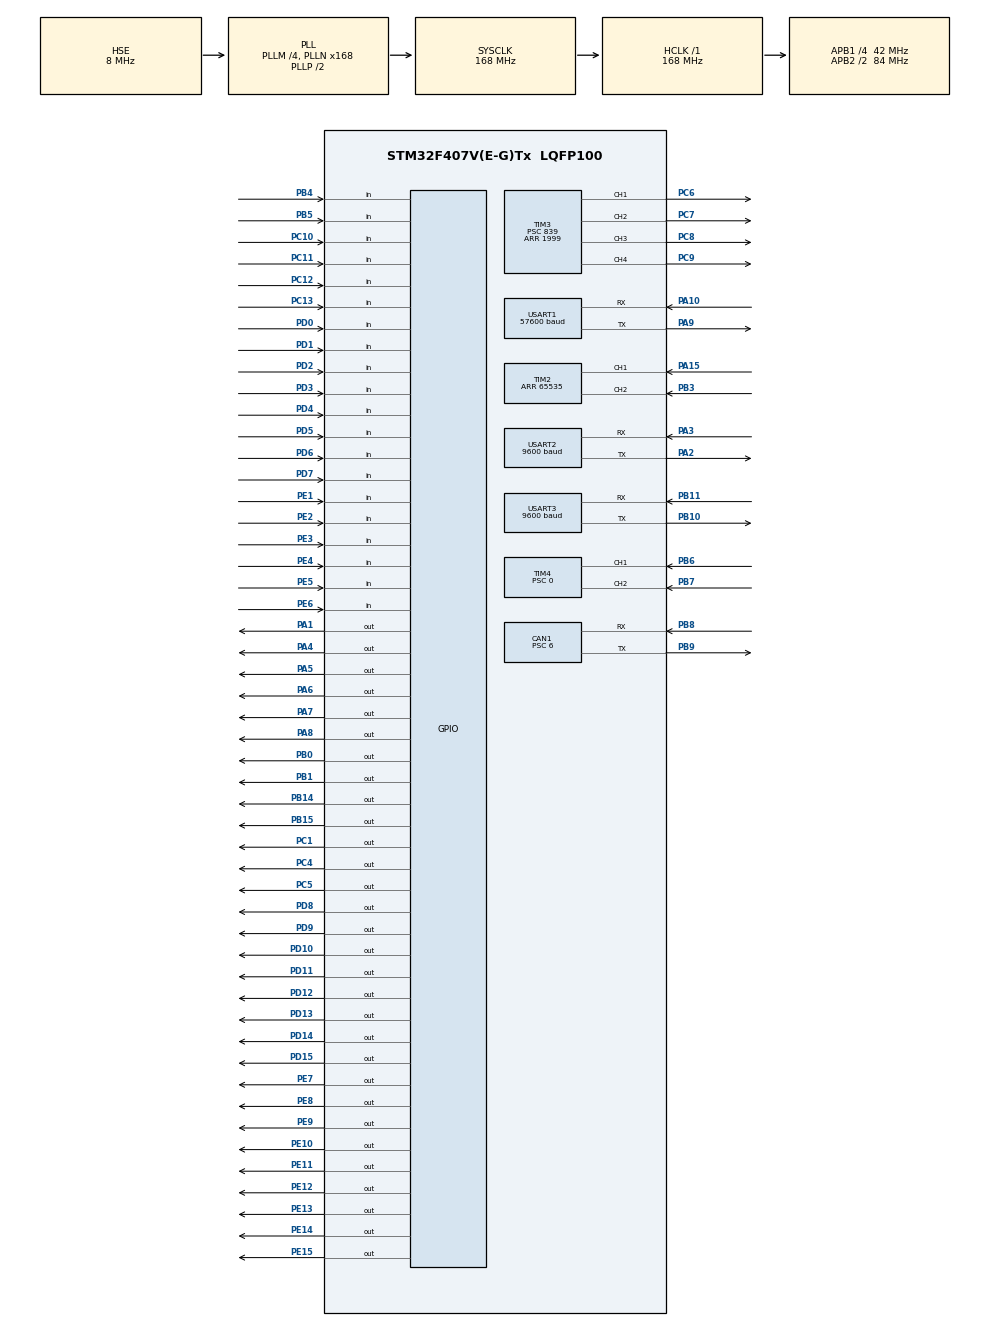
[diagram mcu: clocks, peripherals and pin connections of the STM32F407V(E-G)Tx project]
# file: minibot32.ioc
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CAN1.ABOM=ENABLE
CAN1.BS1=CAN_BS1_11TQ
CAN1.BS2=CAN_BS2_2TQ
CAN1.CalculateBaudRate=500000
CAN1.CalculateTimeBit=2000
CAN1.CalculateTimeQuantum=142.85714285714286
CAN1.Prescaler=6
CAN1.TXFP=ENABLE
Dma.Request0=USART1_RX
Dma.Request1=USART2_RX
Dma.Request2=USART3_RX
Dma.USART1_RX.0.Direction=DMA_PERIPH_TO_MEMORY
Dma.USART1_RX.0.FIFOMode=DMA_FIFOMODE_DISABLE
Dma.USART1_RX.0.Instance=DMA2_Stream2
Dma.USART1_RX.0.MemDataAlignment=DMA_MDATAALIGN_BYTE
Dma.USART1_RX.0.MemInc=DMA_MINC_ENABLE
Dma.USART1_RX.0.Mode=DMA_NORMAL
Dma.USART1_RX.0.PeriphDataAlignment=DMA_PDATAALIGN_BYTE
Dma.USART1_RX.0.PeriphInc=DMA_PINC_DISABLE
Dma.USART1_RX.0.Priority=DMA_PRIORITY_LOW
Dma.USART2_RX.1.Direction=DMA_PERIPH_TO_MEMORY
Dma.USART2_RX.1.FIFOMode=DMA_FIFOMODE_DISABLE
Dma.USART2_RX.1.Instance=DMA1_Stream5
Dma.USART2_RX.1.MemDataAlignment=DMA_MDATAALIGN_BYTE
Dma.USART2_RX.1.MemInc=DMA_MINC_ENABLE
Dma.USART2_RX.1.Mode=DMA_NORMAL
Dma.USART2_RX.1.PeriphDataAlignment=DMA_PDATAALIGN_BYTE
Dma.USART2_RX.1.PeriphInc=DMA_PINC_DISABLE
Dma.USART2_RX.1.Priority=DMA_PRIORITY_LOW
Dma.USART3_RX.2.Direction=DMA_PERIPH_TO_MEMORY
Dma.USART3_RX.2.FIFOMode=DMA_FIFOMODE_DISABLE
Dma.USART3_RX.2.Instance=DMA1_Stream1
Dma.USART3_RX.2.MemDataAlignment=DMA_MDATAALIGN_BYTE
Dma.USART3_RX.2.MemInc=DMA_MINC_ENABLE
Dma.USART3_RX.2.Mode=DMA_NORMAL
Dma.USART3_RX.2.PeriphDataAlignment=DMA_PDATAALIGN_BYTE
Dma.USART3_RX.2.PeriphInc=DMA_PINC_DISABLE
Dma.USART3_RX.2.Priority=DMA_PRIORITY_LOW
FREERTOS.Tasks01=defaultTask,24,128,StartDefaultTask,Default,NULL,Static,defaultTaskBuffer,defaultTaskControlBlock;OutputsTask,24,128,StartOutputsTask,As external,NULL,Static,OutputsTaskBuffer,OutputsTaskControlBlock;InputsTask,24,128,StartInputsTask,As external,NULL,Static,InputsTaskBuffer,InputsTaskControlBlock;ServoTask,24,128,StartServoTask,As external,NULL,Static,ServoTaskBuffer,ServoTaskControlBlock;UartWiFiTask,24,256,StartUartWiFiTask,As external,NULL,Static,UartWiFiTaskBuffer,UartWiFiTaskControlBlock;CanDriversTask,24,128,StartCanDriversTask,As external,NULL,Static,CanDriversTaskBuffer,CanDriversTaskControlBlock;CanTask,24,256,StartCanTask,As external,NULL,Static,CanTaskBuffer,CanTaskControlBlock;MissionsTask,8,256,StartMissionsTask,As external,NULL,Static,MissionsTaskBuffer,MissionsTaskControlBlock
IWDG.Prescaler=IWDG_PRESCALER_32
Mcu.Family=STM32F4
Mcu.Name=STM32F407V(E-G)Tx
Mcu.Package=LQFP100
NVIC.CAN1_RX0_IRQn=true\:5\:0\:false\:false\:true\:true\:true\:true\:true
NVIC.CAN1_SCE_IRQn=true\:5\:0\:false\:false\:true\:true\:true\:true\:true
NVIC.DMA1_Stream1_IRQn=true\:5\:0\:false\:false\:true\:true\:false\:true\:true
NVIC.DMA1_Stream5_IRQn=true\:5\:0\:false\:false\:true\:true\:false\:true\:true
NVIC.DMA2_Stream2_IRQn=true\:5\:0\:false\:false\:true\:true\:false\:true\:true
NVIC.PriorityGroup=NVIC_PRIORITYGROUP_4
NVIC.TIM6_DAC_IRQn=true\:15\:0\:false\:false\:true\:false\:false\:true\:true
NVIC.TimeBase=TIM6_DAC_IRQn
NVIC.TimeBaseIP=TIM6
NVIC.USART1_IRQn=true\:5\:0\:false\:false\:true\:true\:true\:true\:true
NVIC.USART2_IRQn=true\:5\:0\:false\:false\:true\:true\:true\:true\:true
NVIC.USART3_IRQn=true\:5\:0\:false\:false\:true\:true\:true\:true\:true
PA1.PinState=GPIO_PIN_SET
PA1.Signal=GPIO_Output
PA10.Mode=Asynchronous
PA10.Signal=USART1_RX
PA13.Mode=Serial_Wire
PA13.Signal=SYS_JTMS-SWDIO
PA14.Mode=Serial_Wire
PA14.Signal=SYS_JTCK-SWCLK
PA15.Signal=S_TIM2_CH1_ETR
PA2.Mode=Asynchronous
PA2.Signal=USART2_TX
PA3.Mode=Asynchronous
PA3.Signal=USART2_RX
PA4.PinState=GPIO_PIN_SET
PA4.Signal=GPIO_Output
PA5.PinState=GPIO_PIN_SET
PA5.Signal=GPIO_Output
PA6.PinState=GPIO_PIN_SET
PA6.Signal=GPIO_Output
PA7.PinState=GPIO_PIN_SET
PA7.Signal=GPIO_Output
PA8.PinState=GPIO_PIN_SET
PA8.Signal=GPIO_Output
PA9.Mode=Asynchronous
PA9.Signal=USART1_TX
PB0.PinState=GPIO_PIN_SET
PB0.Signal=GPIO_Output
PB1.PinState=GPIO_PIN_SET
PB1.Signal=GPIO_Output
PB10.Mode=Asynchronous
PB10.Signal=USART3_TX
PB11.Mode=Asynchronous
PB11.Signal=USART3_RX
PB14.Signal=GPIO_Output
PB15.Signal=GPIO_Output
PB3.Signal=S_TIM2_CH2
PB4.Signal=GPIO_Input
PB5.Signal=GPIO_Input
PB6.Signal=S_TIM4_CH1
PB7.Signal=S_TIM4_CH2
PB8.Mode=CAN_Activate
PB8.Signal=CAN1_RX
PB9.Mode=CAN_Activate
PB9.Signal=CAN1_TX
PC1.PinState=GPIO_PIN_SET
PC1.Signal=GPIO_Output
PC10.Signal=GPIO_Input
PC11.Signal=GPIO_Input
PC12.Signal=GPIO_Input
PC13-ANTI_TAMP.Signal=GPIO_Input
PC14-OSC32_IN.Mode=LSE-External-Oscillator
PC14-OSC32_IN.Signal=RCC_OSC32_IN
PC15-OSC32_OUT.Mode=LSE-External-Oscillator
PC15-OSC32_OUT.Signal=RCC_OSC32_OUT
PC4.PinState=GPIO_PIN_SET
PC4.Signal=GPIO_Output
PC5.PinState=GPIO_PIN_SET
PC5.Signal=GPIO_Output
PC6.Signal=S_TIM3_CH1
PC7.Signal=S_TIM3_CH2
PC8.Signal=S_TIM3_CH3
PC9.Signal=S_TIM3_CH4
PD0.Signal=GPIO_Input
PD1.Signal=GPIO_Input
PD10.PinState=GPIO_PIN_SET
PD10.Signal=GPIO_Output
PD11.PinState=GPIO_PIN_SET
PD11.Signal=GPIO_Output
PD12.PinState=GPIO_PIN_SET
PD12.Signal=GPIO_Output
PD13.PinState=GPIO_PIN_SET
PD13.Signal=GPIO_Output
PD14.Signal=GPIO_Output
PD15.PinState=GPIO_PIN_SET
PD15.Signal=GPIO_Output
PD2.Signal=GPIO_Input
PD3.Signal=GPIO_Input
PD4.Signal=GPIO_Input
PD5.Signal=GPIO_Input
PD6.Signal=GPIO_Input
PD7.Signal=GPIO_Input
PD8.PinState=GPIO_PIN_SET
PD8.Signal=GPIO_Output
PD9.PinState=GPIO_PIN_SET
PD9.Signal=GPIO_Output
PE1.Signal=GPIO_Input
PE10.PinState=GPIO_PIN_SET
PE10.Signal=GPIO_Output
PE11.PinState=GPIO_PIN_SET
PE11.Signal=GPIO_Output
PE12.PinState=GPIO_PIN_SET
PE12.Signal=GPIO_Output
PE13.PinState=GPIO_PIN_SET
PE13.Signal=GPIO_Output
PE14.PinState=GPIO_PIN_SET
PE14.Signal=GPIO_Output
PE15.PinState=GPIO_PIN_SET
PE15.Signal=GPIO_Output
PE2.Signal=GPIO_Input
PE3.Signal=GPIO_Input
PE4.Signal=GPIO_Input
PE5.Signal=GPIO_Input
PE6.Signal=GPIO_Input
PE7.PinState=GPIO_PIN_SET
PE7.Signal=GPIO_Output
PE8.PinState=GPIO_PIN_SET
PE8.Signal=GPIO_Output
PE9.PinState=GPIO_PIN_SET
PE9.Signal=GPIO_Output
PH0-OSC_IN.Mode=HSE-External-Oscillator
PH0-OSC_IN.Signal=RCC_OSC_IN
PH1-OSC_OUT.Mode=HSE-External-Oscillator
PH1-OSC_OUT.Signal=RCC_OSC_OUT
ProjectManager.HeapSize=0x200
ProjectManager.StackSize=0x400
ProjectManager.TargetToolchain=STM32CubeIDE
RCC.48MHZClocksFreq_Value=84000000
RCC.AHBFreq_Value=168000000
RCC.APB1CLKDivider=RCC_HCLK_DIV4
RCC.APB1Freq_Value=42000000
RCC.APB1TimFreq_Value=84000000
RCC.APB2CLKDivider=RCC_HCLK_DIV2
RCC.APB2Freq_Value=84000000
RCC.APB2TimFreq_Value=168000000
RCC.CortexFreq_Value=168000000
RCC.HCLKFreq_Value=168000000
RCC.HSE_VALUE=8000000
RCC.HSI_VALUE=16000000
RCC.PLLM=4
RCC.PLLN=168
RCC.PLLSourceVirtual=RCC_PLLSOURCE_HSE
RCC.SYSCLKFreq_VALUE=168000000
RCC.SYSCLKSource=RCC_SYSCLKSOURCE_PLLCLK
RCC.VCOOutputFreq_Value=336000000
SH.S_TIM2_CH1_ETR.0=TIM2_CH1,Encoder_Interface
SH.S_TIM2_CH2.0=TIM2_CH2,Encoder_Interface
SH.S_TIM3_CH1.0=TIM3_CH1,PWM Generation1 CH1
SH.S_TIM3_CH2.0=TIM3_CH2,PWM Generation2 CH2
SH.S_TIM3_CH3.0=TIM3_CH3,PWM Generation3 CH3
SH.S_TIM3_CH4.0=TIM3_CH4,PWM Generation4 CH4
SH.S_TIM4_CH1.0=TIM4_CH1,Encoder_Interface
SH.S_TIM4_CH2.0=TIM4_CH2,Encoder_Interface
TIM2.Period=65535
TIM3.AutoReloadPreload=TIM_AUTORELOAD_PRELOAD_ENABLE
TIM3.Channel-PWM\ Generation1\ CH1=TIM_CHANNEL_1
TIM3.Channel-PWM\ Generation2\ CH2=TIM_CHANNEL_2
TIM3.Channel-PWM\ Generation3\ CH3=TIM_CHANNEL_3
TIM3.Channel-PWM\ Generation4\ CH4=TIM_CHANNEL_4
TIM3.OCPolarity_1=TIM_OCPOLARITY_HIGH
TIM3.Period=1999
TIM3.Prescaler=839
TIM4.Period=65535
TIM4.Prescaler=0
USART1.BaudRate=57600
USART1.VirtualMode=VM_ASYNC
USART2.BaudRate=9600
USART2.VirtualMode=VM_ASYNC
USART3.BaudRate=9600
USART3.VirtualMode=VM_ASYNC
VP_FREERTOS_VS_CMSIS_V2.Mode=CMSIS_V2
VP_IWDG_VS_IWDG.Mode=IWDG_Activate
VP_SYS_VS_tim6.Mode=TIM6
VP_TIM3_VS_ClockSourceINT.Mode=Internal
board=custom

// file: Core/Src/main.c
/* USER CODE BEGIN Header */
/**
  ******************************************************************************
  * @file           : main.c
  * @brief          : Main program body
  ******************************************************************************
  * @attention
  *
  * Copyright (c) 2024 STMicroelectronics.
  * All rights reserved.
  *
  * This software is licensed under terms that can be found in the LICENSE file
  * in the root directory of this software component.
  * If no LICENSE file comes with this software, it is provided AS-IS.
  *
  ******************************************************************************
  */
/* USER CODE END Header */
#include "main.h"
#include "cmsis_os.h"
#include "can.h"
#include "dma.h"
#include "iwdg.h"
#include "tim.h"
#include "usart.h"
#include "gpio.h"

/* USER CODE BEGIN Includes */

#include "minibot_config.h"

/* USER CODE END Includes */

/* USER CODE BEGIN PV */

extern DMA_HandleTypeDef RC_UART_DMA;
extern DMA_HandleTypeDef BMS_UART_DMA;
extern DMA_HandleTypeDef WIFI_UART_DMA;

extern uint8_t rc_uart_buff[100];
extern uint8_t bms_uart_buff[100];
extern uint8_t wifi_uart_buff[100];

/* USER CODE END PV */

void SystemClock_Config(void);
void MX_FREERTOS_Init(void);

int main(void)
{

  /* MCU Configuration--------------------------------------------------------*/

  /* Reset of all peripherals, Initializes the Flash interface and the Systick. */
  HAL_Init();

  /* Configure the system clock */
  SystemClock_Config();

  /* Initialize all configured peripherals */
  MX_GPIO_Init();
  MX_DMA_Init();
  MX_USART1_UART_Init();
  MX_USART2_UART_Init();
  MX_USART3_UART_Init();
  MX_TIM2_Init();
  MX_TIM3_Init();
  MX_TIM4_Init();
  MX_IWDG_Init();
  MX_CAN1_Init();
  /* USER CODE BEGIN 2 */
  HAL_Delay(2500);
  HAL_IWDG_Refresh(&hiwdg);
  HAL_UARTEx_ReceiveToIdle_DMA(&WIFI_UART, wifi_uart_buff, sizeof(wifi_uart_buff));
  HAL_UARTEx_ReceiveToIdle_DMA(&BMS_UART, bms_uart_buff, sizeof(bms_uart_buff));
  HAL_UARTEx_ReceiveToIdle_DMA(&RC_UART, rc_uart_buff, sizeof(rc_uart_buff));

  __HAL_DMA_DISABLE_IT(&WIFI_UART_DMA, DMA_IT_HT);
  __HAL_DMA_DISABLE_IT(&BMS_UART_DMA, DMA_IT_HT);
  __HAL_DMA_DISABLE_IT(&RC_UART_DMA, DMA_IT_HT);

  HAL_TIM_Encoder_Start(&htim2, TIM_CHANNEL_1);
  HAL_TIM_Encoder_Start(&htim4, TIM_CHANNEL_1);
  /* USER CODE END 2 */

  /* Init scheduler */
  osKernelInitialize();  /* Call init function for freertos objects (in freertos.c) */
  MX_FREERTOS_Init();

  /* Start scheduler */
  osKernelStart();

  /* We should never get here as control is now taken by the scheduler */
  /* Infinite loop */
  while (1)
  {

  }
}

void SystemClock_Config(void)
{
  RCC_OscInitTypeDef RCC_OscInitStruct = {0};
  RCC_ClkInitTypeDef RCC_ClkInitStruct = {0};

  /** Configure the main internal regulator output voltage
  */
  __HAL_RCC_PWR_CLK_ENABLE();
  __HAL_PWR_VOLTAGESCALING_CONFIG(PWR_REGULATOR_VOLTAGE_SCALE1);

  /** Initializes the RCC Oscillators according to the specified parameters
  * in the RCC_OscInitTypeDef structure.
  */
  RCC_OscInitStruct.OscillatorType = RCC_OSCILLATORTYPE_LSI|RCC_OSCILLATORTYPE_HSE;
  RCC_OscInitStruct.HSEState = RCC_HSE_ON;
  RCC_OscInitStruct.LSIState = RCC_LSI_ON;
  RCC_OscInitStruct.PLL.PLLState = RCC_PLL_ON;
  RCC_OscInitStruct.PLL.PLLSource = RCC_PLLSOURCE_HSE;
  RCC_OscInitStruct.PLL.PLLM = 4;
  RCC_OscInitStruct.PLL.PLLN = 168;
  RCC_OscInitStruct.PLL.PLLP = RCC_PLLP_DIV2;
  RCC_OscInitStruct.PLL.PLLQ = 4;
  if (HAL_RCC_OscConfig(&RCC_OscInitStruct) != HAL_OK)
  {
    Error_Handler();
  }

  /** Initializes the CPU, AHB and APB buses clocks
  */
  RCC_ClkInitStruct.ClockType = RCC_CLOCKTYPE_HCLK|RCC_CLOCKTYPE_SYSCLK
                              |RCC_CLOCKTYPE_PCLK1|RCC_CLOCKTYPE_PCLK2;
  RCC_ClkInitStruct.SYSCLKSource = RCC_SYSCLKSOURCE_PLLCLK;
  RCC_ClkInitStruct.AHBCLKDivider = RCC_SYSCLK_DIV1;
  RCC_ClkInitStruct.APB1CLKDivider = RCC_HCLK_DIV4;
  RCC_ClkInitStruct.APB2CLKDivider = RCC_HCLK_DIV2;

  if (HAL_RCC_ClockConfig(&RCC_ClkInitStruct, FLASH_LATENCY_5) != HAL_OK)
  {
    Error_Handler();
  }
}

void HAL_TIM_PeriodElapsedCallback(TIM_HandleTypeDef *htim)
{
  if (htim->Instance == TIM6) {
    HAL_IncTick();
  }
}

void Error_Handler(void)
{
  __disable_irq();
  while (1)
  {
  }
}

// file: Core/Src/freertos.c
/* USER CODE BEGIN Header */
/**
  ******************************************************************************
  * File Name          : freertos.c
  * Description        : Code for freertos applications
  ******************************************************************************
  * @attention
  *
  * Copyright (c) 2024 STMicroelectronics.
  * All rights reserved.
  *
  * This software is licensed under terms that can be found in the LICENSE file
  * in the root directory of this software component.
  * If no LICENSE file comes with this software, it is provided AS-IS.
  *
  ******************************************************************************
  */
/* USER CODE END Header */

#include "FreeRTOS.h"
#include "task.h"
#include "main.h"
#include "cmsis_os.h"

/* USER CODE BEGIN Includes */

#include "minibot_config.h"
#include "outputs.h"
#include "inputs.h"
#include "servo_control.h"
#include "uart_wifi.h"
#include "drivers_control.h"
#include "canbus.h"

/* USER CODE END Includes */

typedef StaticTask_t osStaticThreadDef_t;

/* USER CODE BEGIN Variables */

GlobDataTypeDef globData;
MinibotConfigTypeDef minibotConfig;
ContrlMsgTypeDef contrlMsg;
StatusMsgTypeDef statusMsg;

/* USER CODE END Variables */
/* Definitions for defaultTask */
osThreadId_t defaultTaskHandle;
uint32_t defaultTaskBuffer[ 128 ];
osStaticThreadDef_t defaultTaskControlBlock;
const osThreadAttr_t defaultTask_attributes = {
  .name = "defaultTask",
  .cb_mem = &defaultTaskControlBlock,
  .cb_size = sizeof(defaultTaskControlBlock),
  .stack_mem = &defaultTaskBuffer[0],
  .stack_size = sizeof(defaultTaskBuffer),
  .priority = (osPriority_t) osPriorityNormal,
};
/* Definitions for OutputsTask */
osThreadId_t OutputsTaskHandle;
uint32_t OutputsTaskBuffer[ 128 ];
osStaticThreadDef_t OutputsTaskControlBlock;
const osThreadAttr_t OutputsTask_attributes = {
  .name = "OutputsTask",
  .cb_mem = &OutputsTaskControlBlock,
  .cb_size = sizeof(OutputsTaskControlBlock),
  .stack_mem = &OutputsTaskBuffer[0],
  .stack_size = sizeof(OutputsTaskBuffer),
  .priority = (osPriority_t) osPriorityNormal,
};
/* Definitions for InputsTask */
osThreadId_t InputsTaskHandle;
uint32_t InputsTaskBuffer[ 128 ];
osStaticThreadDef_t InputsTaskControlBlock;
const osThreadAttr_t InputsTask_attributes = {
  .name = "InputsTask",
  .cb_mem = &InputsTaskControlBlock,
  .cb_size = sizeof(InputsTaskControlBlock),
  .stack_mem = &InputsTaskBuffer[0],
  .stack_size = sizeof(InputsTaskBuffer),
  .priority = (osPriority_t) osPriorityNormal,
};
/* Definitions for ServoTask */
osThreadId_t ServoTaskHandle;
uint32_t ServoTaskBuffer[ 128 ];
osStaticThreadDef_t ServoTaskControlBlock;
const osThreadAttr_t ServoTask_attributes = {
  .name = "ServoTask",
  .cb_mem = &ServoTaskControlBlock,
  .cb_size = sizeof(ServoTaskControlBlock),
  .stack_mem = &ServoTaskBuffer[0],
  .stack_size = sizeof(ServoTaskBuffer),
  .priority = (osPriority_t) osPriorityNormal,
};
/* Definitions for UartWiFiTask */
osThreadId_t UartWiFiTaskHandle;
uint32_t UartWiFiTaskBuffer[ 256 ];
osStaticThreadDef_t UartWiFiTaskControlBlock;
const osThreadAttr_t UartWiFiTask_attributes = {
  .name = "UartWiFiTask",
  .cb_mem = &UartWiFiTaskControlBlock,
  .cb_size = sizeof(UartWiFiTaskControlBlock),
  .stack_mem = &UartWiFiTaskBuffer[0],
  .stack_size = sizeof(UartWiFiTaskBuffer),
  .priority = (osPriority_t) osPriorityNormal,
};
/* Definitions for CanDriversTask */
osThreadId_t CanDriversTaskHandle;
uint32_t CanDriversTaskBuffer[ 128 ];
osStaticThreadDef_t CanDriversTaskControlBlock;
const osThreadAttr_t CanDriversTask_attributes = {
  .name = "CanDriversTask",
  .cb_mem = &CanDriversTaskControlBlock,
  .cb_size = sizeof(CanDriversTaskControlBlock),
  .stack_mem = &CanDriversTaskBuffer[0],
  .stack_size = sizeof(CanDriversTaskBuffer),
  .priority = (osPriority_t) osPriorityNormal,
};
/* Definitions for CanTask */
osThreadId_t CanTaskHandle;
uint32_t CanTaskBuffer[ 256 ];
osStaticThreadDef_t CanTaskControlBlock;
const osThreadAttr_t CanTask_attributes = {
  .name = "CanTask",
  .cb_mem = &CanTaskControlBlock,
  .cb_size = sizeof(CanTaskControlBlock),
  .stack_mem = &CanTaskBuffer[0],
  .stack_size = sizeof(CanTaskBuffer),
  .priority = (osPriority_t) osPriorityNormal,
};
/* Definitions for MissionsTask */
osThreadId_t MissionsTaskHandle;
uint32_t MissionsTaskBuffer[ 256 ];
osStaticThreadDef_t MissionsTaskControlBlock;
const osThreadAttr_t MissionsTask_attributes = {
  .name = "MissionsTask",
  .cb_mem = &MissionsTaskControlBlock,
  .cb_size = sizeof(MissionsTaskControlBlock),
  .stack_mem = &MissionsTaskBuffer[0],
  .stack_size = sizeof(MissionsTaskBuffer),
  .priority = (osPriority_t) osPriorityLow,
};

void StartDefaultTask(void *argument);
extern void StartOutputsTask(void *argument);
extern void StartInputsTask(void *argument);
extern void StartServoTask(void *argument);
extern void StartUartWiFiTask(void *argument);
extern void StartCanDriversTask(void *argument);
extern void StartCanTask(void *argument);
extern void StartMissionsTask(void *argument);

void MX_FREERTOS_Init(void); /* (MISRA C 2004 rule 8.1) */

void MX_FREERTOS_Init(void) {

  /* Create the thread(s) */
  /* creation of defaultTask */
  defaultTaskHandle = osThreadNew(StartDefaultTask, NULL, &defaultTask_attributes);

  /* creation of OutputsTask */
  OutputsTaskHandle = osThreadNew(StartOutputsTask, NULL, &OutputsTask_attributes);

  /* creation of InputsTask */
  InputsTaskHandle = osThreadNew(StartInputsTask, NULL, &InputsTask_attributes);

  /* creation of ServoTask */
  ServoTaskHandle = osThreadNew(StartServoTask, NULL, &ServoTask_attributes);

  /* creation of UartWiFiTask */
  UartWiFiTaskHandle = osThreadNew(StartUartWiFiTask, NULL, &UartWiFiTask_attributes);

  /* creation of CanDriversTask */
  CanDriversTaskHandle = osThreadNew(StartCanDriversTask, NULL, &CanDriversTask_attributes);

  /* creation of CanTask */
  CanTaskHandle = osThreadNew(StartCanTask, NULL, &CanTask_attributes);

  /* creation of MissionsTask */
  MissionsTaskHandle = osThreadNew(StartMissionsTask, NULL, &MissionsTask_attributes);

}

void StartDefaultTask(void *argument)
{
  /* USER CODE BEGIN StartDefaultTask */
  /* Infinite loop */
  for(;;)
  {
    osDelay(1000);
  }
  /* USER CODE END StartDefaultTask */
}
